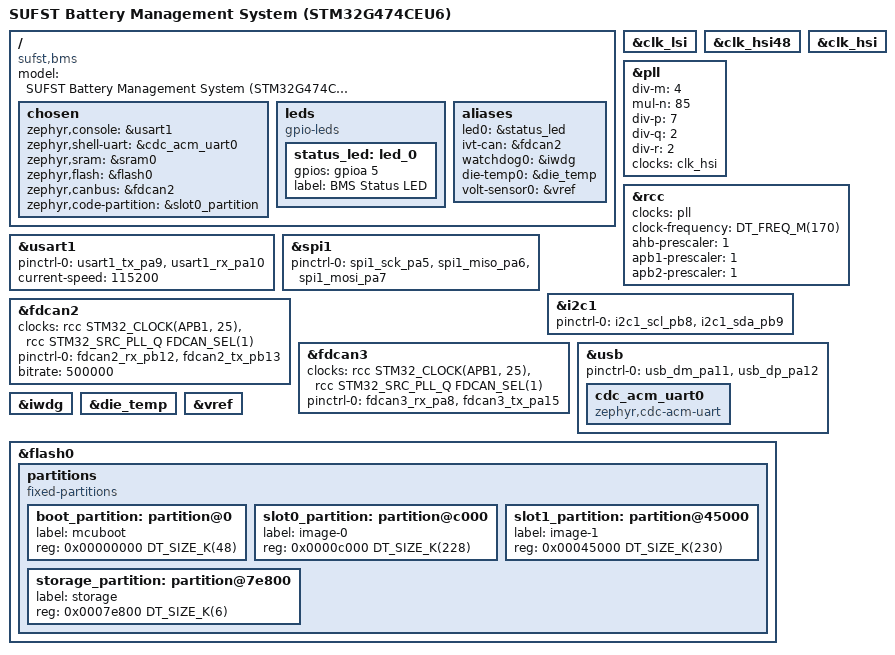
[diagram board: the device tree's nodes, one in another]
/*
 * SUFST BMS Custom Board DeviceTree (STM32G474CEU6 - UFQFPN48)
 * SPDX-License-Identifier: Apache-2.0
 */

/dts-v1/;
#include <st/g4/stm32g474Xe.dtsi>
#include <st/g4/stm32g474c(b-c-e)ux-pinctrl.dtsi>

/ {
	model = "SUFST Battery Management System (STM32G474CEU6)";
	compatible = "sufst,bms", "st,stm32g474";

	chosen {
		zephyr,console = &usart1;
		zephyr,shell-uart = &cdc_acm_uart0;
		zephyr,sram = &sram0;
		zephyr,flash = &flash0;
		zephyr,canbus = &fdcan2;
		zephyr,code-partition = &slot0_partition;
	};

	leds: leds {
		compatible = "gpio-leds";

		status_led: led_0 {
			/* Update pin to match BMS schematic status LED */
			gpios = <&gpioa 5 GPIO_ACTIVE_HIGH>;
			label = "BMS Status LED";
		};
	};

	aliases {
		led0 = &status_led;
		ivt-can = &fdcan2;
		watchdog0 = &iwdg;
		die-temp0 = &die_temp;
		volt-sensor0 = &vref;
	};
};

&clk_lsi {
	status = "okay";
};

&clk_hsi48 {
	status = "okay";
};

/*
 * Default clock setup uses internal 16 MHz HSI -> PLL -> 170 MHz SYSCLK
 * so the board boots without depending on an external crystal.
 * When using an external HSE crystal on the PCB, enable &clk_hse and
 * switch &pll clocks to <&clk_hse>.
 */
&clk_hsi {
	status = "okay";
};

&pll {
	div-m = <4>;
	mul-n = <85>;
	div-p = <7>;
	div-q = <2>;
	div-r = <2>;
	clocks = <&clk_hsi>;
	status = "okay";
};

&rcc {
	clocks = <&pll>;
	clock-frequency = <DT_FREQ_M(170)>;
	ahb-prescaler = <1>;
	apb1-prescaler = <1>;
	apb2-prescaler = <1>;
};

&usart1 {
	pinctrl-0 = <&usart1_tx_pa9 &usart1_rx_pa10>;
	pinctrl-names = "default";
	current-speed = <115200>;
	status = "okay";
};

&spi1 {
	pinctrl-0 = <&spi1_sck_pa5 &spi1_miso_pa6 &spi1_mosi_pa7>;
	pinctrl-names = "default";
	status = "okay";
};

&i2c1 {
	pinctrl-0 = <&i2c1_scl_pb8 &i2c1_sda_pb9>;
	pinctrl-names = "default";
	status = "okay";
};

/*
 * PA11 / PA12 are the only USB D- / D+ pins on the 48-pin package, so CAN
 * uses FDCAN2 and FDCAN3 instead of FDCAN1. Pin choices are placeholders
 * until the PCB is final (alternatives: FDCAN2 on PB5/PB6, FDCAN3 on PB3/PB4,
 * FDCAN1 on PB8/PB9 - note PB8 is BOOT0).
 */
&fdcan2 {
	clocks = <&rcc STM32_CLOCK(APB1, 25)>,
		 <&rcc STM32_SRC_PLL_Q FDCAN_SEL(1)>;
	pinctrl-0 = <&fdcan2_rx_pb12 &fdcan2_tx_pb13>;
	pinctrl-names = "default";
	bitrate = <500000>; /* IVT-S factory default */
	status = "okay";
};

&fdcan3 {
	clocks = <&rcc STM32_CLOCK(APB1, 25)>,
		 <&rcc STM32_SRC_PLL_Q FDCAN_SEL(1)>;
	pinctrl-0 = <&fdcan3_rx_pa8 &fdcan3_tx_pa15>;
	pinctrl-names = "default";
	status = "okay";
};

/*
 * USB full-speed device, clocked from HSI48 (default CLK48 source). HSI48 is
 * trimmed against USB SOF by the CRS, enabled in src/bms_usb.c.
 */
zephyr_udc0: &usb {
	pinctrl-0 = <&usb_dm_pa11 &usb_dp_pa12>;
	pinctrl-names = "default";
	status = "okay";

	cdc_acm_uart0: cdc_acm_uart0 {
		compatible = "zephyr,cdc-acm-uart";
	};
};

&iwdg {
	status = "okay";
};

&die_temp {
	status = "okay";
};

&vref {
	status = "okay";
};

&flash0 {
	partitions {
		compatible = "fixed-partitions";
		#address-cells = <1>;
		#size-cells = <1>;

		boot_partition: partition@0 {
			label = "mcuboot";
			reg = <0x00000000 DT_SIZE_K(48)>;
		};

		slot0_partition: partition@c000 {
			label = "image-0";
			reg = <0x0000c000 DT_SIZE_K(228)>;
		};

		slot1_partition: partition@45000 {
			label = "image-1";
			reg = <0x00045000 DT_SIZE_K(230)>;
		};

		storage_partition: partition@7e800 {
			label = "storage";
			reg = <0x0007e800 DT_SIZE_K(6)>;
		};
	};
};

